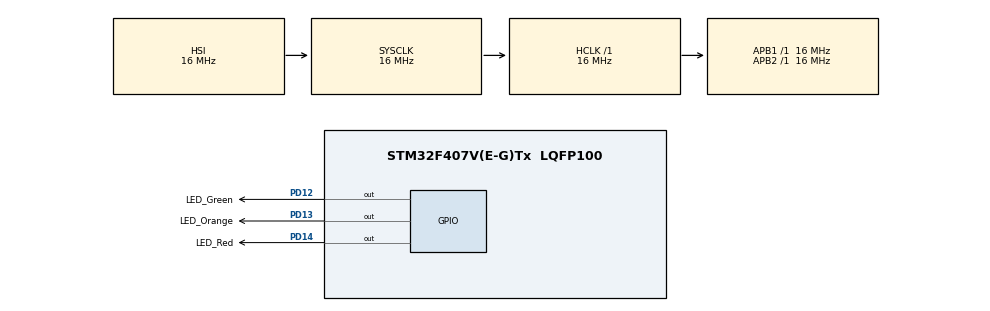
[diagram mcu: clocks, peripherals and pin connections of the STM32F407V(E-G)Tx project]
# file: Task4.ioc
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Dma.MEMTOMEM.0.Direction=DMA_MEMORY_TO_MEMORY
Dma.MEMTOMEM.0.FIFOMode=DMA_FIFOMODE_ENABLE
Dma.MEMTOMEM.0.FIFOThreshold=DMA_FIFO_THRESHOLD_FULL
Dma.MEMTOMEM.0.Instance=DMA2_Stream0
Dma.MEMTOMEM.0.MemBurst=DMA_MBURST_SINGLE
Dma.MEMTOMEM.0.MemDataAlignment=DMA_MDATAALIGN_BYTE
Dma.MEMTOMEM.0.MemInc=DMA_MINC_ENABLE
Dma.MEMTOMEM.0.Mode=DMA_NORMAL
Dma.MEMTOMEM.0.PeriphBurst=DMA_PBURST_SINGLE
Dma.MEMTOMEM.0.PeriphDataAlignment=DMA_PDATAALIGN_BYTE
Dma.MEMTOMEM.0.PeriphInc=DMA_PINC_ENABLE
Dma.MEMTOMEM.0.Priority=DMA_PRIORITY_LOW
Dma.Request0=MEMTOMEM
Mcu.Family=STM32F4
Mcu.Name=STM32F407V(E-G)Tx
Mcu.Package=LQFP100
NVIC.DMA2_Stream0_IRQn=true\:0\:0\:false\:false\:true\:true\:true\:true
NVIC.PriorityGroup=NVIC_PRIORITYGROUP_4
PD12.GPIO_Label=LED_Green
PD12.Signal=GPIO_Output
PD13.GPIO_Label=LED_Orange
PD13.Signal=GPIO_Output
PD14.GPIO_Label=LED_Red
PD14.Signal=GPIO_Output
ProjectManager.HeapSize=0x200
ProjectManager.StackSize=0x400
ProjectManager.TargetToolchain=Makefile
RCC.AHBFreq_Value=16000000
RCC.APB1Freq_Value=16000000
RCC.APB2Freq_Value=16000000
RCC.CortexFreq_Value=16000000
RCC.HSE_VALUE=25000000
RCC.HSI_VALUE=16000000
RCC.LSE_VALUE=32768
RCC.SYSCLKFreq_VALUE=16000000
RCC.VCOOutputFreq_Value=192000000
board=custom

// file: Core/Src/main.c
/* USER CODE BEGIN Header */
/**
 ******************************************************************************
 * @file           : main.c
 * @brief          : Main program body
 ******************************************************************************
 * @attention
 *
 * Copyright (c) 2025 STMicroelectronics.
 * All rights reserved.
 *
 * This software is licensed under terms that can be found in the LICENSE file
 * in the root directory of this software component.
 * If no LICENSE file comes with this software, it is provided AS-IS.
 *
 ******************************************************************************
 */
/* USER CODE END Header */
#include "main.h"
#include "string.h"

/* USER CODE BEGIN PD */
#define ARR2_SIZE 3
#define ARR1_SIZE 20000
/* USER CODE END PD */

DMA_HandleTypeDef hdma_memtomem_dma2_stream0;

void SystemClock_Config(void);
static void MX_GPIO_Init(void);
static void MX_DMA_Init(void);
/* USER CODE BEGIN PFP */
void DAM2_CLBK();

/* USER CODE END PFP */

/* USER CODE BEGIN 0 */
typedef enum
{
    STARTED = 0,
    Finished = 1

} DMA_STATE_t;

volatile DMA_STATE_t DMA_STATE = STARTED;
uint8_t Arr1_src[ARR1_SIZE];
uint8_t Arr1_dst[ARR1_SIZE];
int Arr_SRC[3] = {1, 2, 3};
int Arr_DST[ARR2_SIZE];
void DAM2_CLBK()
{
    HAL_GPIO_WritePin(LED_Orange_GPIO_Port, LED_Orange_Pin, GPIO_PIN_SET);
    DMA_STATE = Finished;
}

/* USER CODE END 0 */

int main(void)
{

    /* USER CODE BEGIN 1 */
    for ( int i = 0 ; i <ARR1_SIZE; i++){
        Arr1_src[i] = (uint8_t) (i&0xff);
    }
    /* USER CODE END 1 */

    /* MCU
     * Configuration--------------------------------------------------------*/

    /* Reset of all peripherals, Initializes the Flash interface and the
     * Systick. */
    HAL_Init();

    /* Configure the system clock */
    SystemClock_Config();

    /* Initialize all configured peripherals */
    MX_GPIO_Init();
    MX_DMA_Init();
    /* USER CODE BEGIN 2 */
    hdma_memtomem_dma2_stream0.XferCpltCallback = DAM2_CLBK;

    // HAL_GPIO_WritePin(LED_Green_GPIO_Port, LED_Green_Pin, GPIO_PIN_RESET);
    // HAL_Delay(1000);
    // HAL_DMA_Start_IT(&hdma_memtomem_dma2_stream0, (uint32_t)Arr_SRC,
    //                  (uint32_t)Arr_DST, sizeof(int) * ARR2_SIZE);
    // HAL_GPIO_WritePin(LED_Green_GPIO_Port, LED_Green_Pin, GPIO_PIN_SET);
    DMA_STATE = STARTED;
    // uint8_t buff_size = strlen(Arr1);
    memset(Arr1_dst, 0, sizeof(Arr1_dst));
    HAL_DMA_Start_IT(&hdma_memtomem_dma2_stream0, (uint32_t)Arr1_src,
                     (uint32_t)Arr1_dst, sizeof(Arr1_src));
    /* USER CODE END 2 */

    /* Infinite loop */
    /* USER CODE BEGIN WHILE */
    while (1)
    {
        if (DMA_STATE == STARTED)
        {
            HAL_GPIO_TogglePin(LED_Green_GPIO_Port, LED_Green_Pin);
            HAL_Delay(50);
        }
        else
        {
            HAL_GPIO_WritePin(LED_Red_GPIO_Port, LED_Red_Pin, GPIO_PIN_SET);
        }

        /* USER CODE END WHILE */

    }
}

void SystemClock_Config(void)
{
    RCC_OscInitTypeDef RCC_OscInitStruct = {0};
    RCC_ClkInitTypeDef RCC_ClkInitStruct = {0};

    /** Configure the main internal regulator output voltage
     */
    __HAL_RCC_PWR_CLK_ENABLE();
    __HAL_PWR_VOLTAGESCALING_CONFIG(PWR_REGULATOR_VOLTAGE_SCALE1);

    /** Initializes the RCC Oscillators according to the specified parameters
     * in the RCC_OscInitTypeDef structure.
     */
    RCC_OscInitStruct.OscillatorType = RCC_OSCILLATORTYPE_HSI;
    RCC_OscInitStruct.HSIState = RCC_HSI_ON;
    RCC_OscInitStruct.HSICalibrationValue = RCC_HSICALIBRATION_DEFAULT;
    RCC_OscInitStruct.PLL.PLLState = RCC_PLL_NONE;
    if (HAL_RCC_OscConfig(&RCC_OscInitStruct) != HAL_OK)
    {
        Error_Handler();
    }

    /** Initializes the CPU, AHB and APB buses clocks
     */
    RCC_ClkInitStruct.ClockType = RCC_CLOCKTYPE_HCLK | RCC_CLOCKTYPE_SYSCLK |
                                  RCC_CLOCKTYPE_PCLK1 | RCC_CLOCKTYPE_PCLK2;
    RCC_ClkInitStruct.SYSCLKSource = RCC_SYSCLKSOURCE_HSI;
    RCC_ClkInitStruct.AHBCLKDivider = RCC_SYSCLK_DIV1;
    RCC_ClkInitStruct.APB1CLKDivider = RCC_HCLK_DIV1;
    RCC_ClkInitStruct.APB2CLKDivider = RCC_HCLK_DIV1;

    if (HAL_RCC_ClockConfig(&RCC_ClkInitStruct, FLASH_LATENCY_0) != HAL_OK)
    {
        Error_Handler();
    }
}

static void MX_DMA_Init(void)
{

    /* DMA controller clock enable */
    __HAL_RCC_DMA2_CLK_ENABLE();

    /* Configure DMA request hdma_memtomem_dma2_stream0 on DMA2_Stream0 */
    hdma_memtomem_dma2_stream0.Instance = DMA2_Stream0;
    hdma_memtomem_dma2_stream0.Init.Channel = DMA_CHANNEL_0;
    hdma_memtomem_dma2_stream0.Init.Direction = DMA_MEMORY_TO_MEMORY;
    hdma_memtomem_dma2_stream0.Init.PeriphInc = DMA_PINC_ENABLE;
    hdma_memtomem_dma2_stream0.Init.MemInc = DMA_MINC_ENABLE;
    hdma_memtomem_dma2_stream0.Init.PeriphDataAlignment = DMA_PDATAALIGN_BYTE;
    hdma_memtomem_dma2_stream0.Init.MemDataAlignment = DMA_MDATAALIGN_BYTE;
    hdma_memtomem_dma2_stream0.Init.Mode = DMA_NORMAL;
    hdma_memtomem_dma2_stream0.Init.Priority = DMA_PRIORITY_LOW;
    hdma_memtomem_dma2_stream0.Init.FIFOMode = DMA_FIFOMODE_ENABLE;
    hdma_memtomem_dma2_stream0.Init.FIFOThreshold = DMA_FIFO_THRESHOLD_FULL;
    hdma_memtomem_dma2_stream0.Init.MemBurst = DMA_MBURST_SINGLE;
    hdma_memtomem_dma2_stream0.Init.PeriphBurst = DMA_PBURST_SINGLE;
    if (HAL_DMA_Init(&hdma_memtomem_dma2_stream0) != HAL_OK)
    {
        Error_Handler();
    }

    /* DMA interrupt init */
    /* DMA2_Stream0_IRQn interrupt configuration */
    HAL_NVIC_SetPriority(DMA2_Stream0_IRQn, 0, 0);
    HAL_NVIC_EnableIRQ(DMA2_Stream0_IRQn);
}

static void MX_GPIO_Init(void)
{
    GPIO_InitTypeDef GPIO_InitStruct = {0};

    /* GPIO Ports Clock Enable */
    __HAL_RCC_GPIOD_CLK_ENABLE();

    /*Configure GPIO pin Output Level */
    HAL_GPIO_WritePin(GPIOD, LED_Green_Pin | LED_Orange_Pin | LED_Red_Pin,
                      GPIO_PIN_RESET);

    /*Configure GPIO pins : LED_Green_Pin LED_Orange_Pin LED_Red_Pin */
    GPIO_InitStruct.Pin = LED_Green_Pin | LED_Orange_Pin | LED_Red_Pin;
    GPIO_InitStruct.Mode = GPIO_MODE_OUTPUT_PP;
    GPIO_InitStruct.Pull = GPIO_NOPULL;
    GPIO_InitStruct.Speed = GPIO_SPEED_FREQ_LOW;
    HAL_GPIO_Init(GPIOD, &GPIO_InitStruct);

}

void Error_Handler(void)
{
    /* USER CODE BEGIN Error_Handler_Debug */
    /* User can add his own implementation to report the HAL error return state
     */
    __disable_irq();
    while (1)
    {
    }
    /* USER CODE END Error_Handler_Debug */
}

#ifdef USE_FULL_ASSERT
/**
 * @brief  Reports the name of the source file and the source line number
 *         where the assert_param error has occurred.
 * @param  file: pointer to the source file name
 * @param  line: assert_param error line source number
 * @retval None
 */
void assert_failed(uint8_t* file, uint32_t line)
{
    /* USER CODE BEGIN 6 */
    /* User can add his own implementation to report the file name and line
       number, ex: printf("Wrong parameters value: file %s on line %d\r\n",
       file, line) */
    /* USER CODE END 6 */
}
#endif /* USE_FULL_ASSERT */
